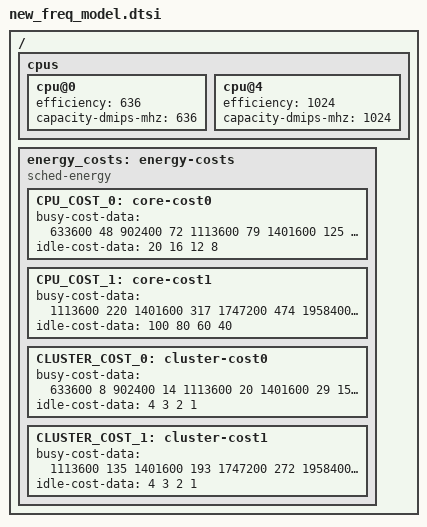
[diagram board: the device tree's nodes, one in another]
/*
 * Auto-generated legacy EAS energy model for incorporation in SoC device tree.
 * Generated by freqbench postprocessing scripts using freqbench results.
 * More info at https://github.com/kdrag0n/freqbench
 */

/ {
	cpus {
		cpu@0 {
			efficiency = <636>;
			capacity-dmips-mhz = <636>;
		};

		cpu@4 {
			efficiency = <1024>;
			capacity-dmips-mhz = <1024>;
		};
	};

	energy_costs: energy-costs {
		compatible = "sched-energy";

		CPU_COST_0: core-cost0 {
			busy-cost-data = <
				  633600   48
				  902400   72
				 1113600   79
				 1401600  125
				 1536000  134
				 1747200  179
				 1843200  228
			>;
			idle-cost-data = <
				20 16 12 8
			>;
		};

		CPU_COST_1: core-cost1 {
			busy-cost-data = <
				 1113600  220
				 1401600  317
				 1747200  474
				 1958400  578
				 2150400  694
				 2208000  736
			>;
			idle-cost-data = <
				100 80 60 40
			>;
		};

		CLUSTER_COST_0: cluster-cost0 {
			busy-cost-data = <
				 633600    8
				 902400   14
				 1113600   20
				 1401600   29
				 1536000   35
				 1747200   49
				 1843200   62
			>;
			idle-cost-data = <
				4 3 2 1
			>;
		};

		CLUSTER_COST_1: cluster-cost1 {
			busy-cost-data = <
				 1113600  135
				 1401600  193
				 1747200  272
				 1958400  363
				 2150400  519
				 2208000  585
			>;
			idle-cost-data = <
				4 3 2 1
			>;
		};
	};
};
